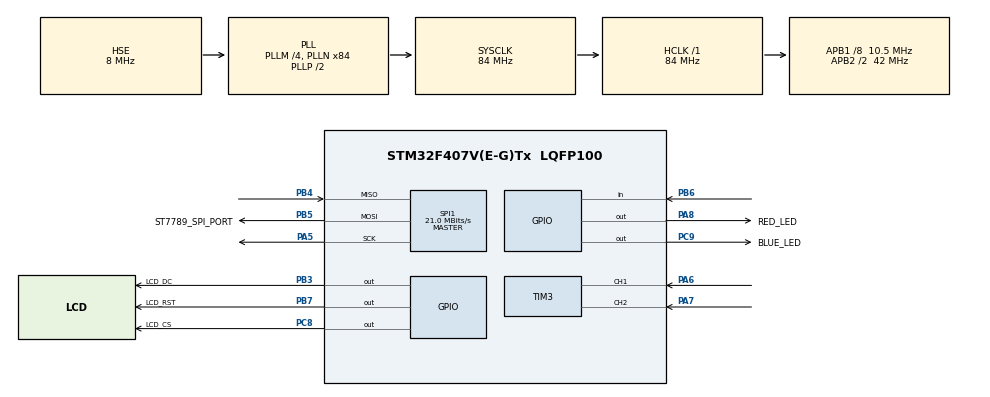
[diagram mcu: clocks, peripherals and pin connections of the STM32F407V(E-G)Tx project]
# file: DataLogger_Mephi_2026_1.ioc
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Mcu.Family=STM32F4
Mcu.Name=STM32F407V(E-G)Tx
Mcu.Package=LQFP100
NVIC.PriorityGroup=NVIC_PRIORITYGROUP_4
PA13.Mode=Serial_Wire
PA13.Signal=SYS_JTMS-SWDIO
PA14.Mode=Serial_Wire
PA14.Signal=SYS_JTCK-SWCLK
PA5.Mode=Full_Duplex_Master
PA5.Signal=SPI1_SCK
PA6.Signal=S_TIM3_CH1
PA7.Signal=S_TIM3_CH2
PA8.GPIO_Label=RED_LED
PA8.Signal=GPIO_Output
PB3.GPIO_Label=LCD_DC
PB3.Signal=GPIO_Output
PB4.Mode=Full_Duplex_Master
PB4.Signal=SPI1_MISO
PB5.GPIO_Label=ST7789_SPI_PORT
PB5.Mode=Full_Duplex_Master
PB5.Signal=SPI1_MOSI
PB6.GPIO_PuPd=GPIO_PULLUP
PB6.Signal=GPIO_Input
PB7.GPIO_Label=LCD_RST
PB7.Signal=GPIO_Output
PC8.GPIO_Label=LCD_CS
PC8.Signal=GPIO_Output
PC9.GPIO_Label=BLUE_LED
PC9.Signal=GPIO_Output
PH0-OSC_IN.Mode=HSE-External-Oscillator
PH0-OSC_IN.Signal=RCC_OSC_IN
PH1-OSC_OUT.Mode=HSE-External-Oscillator
PH1-OSC_OUT.Signal=RCC_OSC_OUT
ProjectManager.HeapSize=0x200
ProjectManager.StackSize=0x400
ProjectManager.TargetToolchain=CMake
RCC.48MHZClocksFreq_Value=42000000
RCC.AHBFreq_Value=84000000
RCC.APB1CLKDivider=RCC_HCLK_DIV8
RCC.APB1Freq_Value=10500000
RCC.APB1TimFreq_Value=21000000
RCC.APB2CLKDivider=RCC_HCLK_DIV2
RCC.APB2Freq_Value=42000000
RCC.APB2TimFreq_Value=84000000
RCC.CortexFreq_Value=84000000
RCC.HCLKFreq_Value=84000000
RCC.HSE_VALUE=8000000
RCC.HSI_VALUE=16000000
RCC.LSE_VALUE=32768
RCC.PLLM=4
RCC.PLLN=84
RCC.PLLSourceVirtual=RCC_PLLSOURCE_HSE
RCC.SYSCLKFreq_VALUE=84000000
RCC.SYSCLKSource=RCC_SYSCLKSOURCE_PLLCLK
RCC.VCOOutputFreq_Value=168000000
SH.S_TIM3_CH1.0=TIM3_CH1,Encoder_Interface
SH.S_TIM3_CH2.0=TIM3_CH2,Encoder_Interface
SPI1.CalculateBaudRate=21.0 MBits/s
SPI1.Direction=SPI_DIRECTION_2LINES
SPI1.Mode=SPI_MODE_MASTER
SPI1.VirtualType=VM_MASTER
TIM3.EncoderMode=TIM_ENCODERMODE_TI12
TIM3.IC1Polarity=TIM_ICPOLARITY_FALLING
TIM6.Period=999
TIM6.Prescaler=83
VP_TIM6_VS_ClockSourceINT.Mode=Enable_Timer
board=custom

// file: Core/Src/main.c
/* USER CODE BEGIN Header */
/**
  ******************************************************************************
  * @file           : main.c
  * @brief          : Main program body
  ******************************************************************************
  * @attention
  *
  * Copyright (c) 2026 STMicroelectronics.
  * All rights reserved.
  *
  * This software is licensed under terms that can be found in the LICENSE file
  * in the root directory of this software component.
  * If no LICENSE file comes with this software, it is provided AS-IS.
  *
  ******************************************************************************
  */
/* USER CODE END Header */
#include "main.h"

/* USER CODE BEGIN Includes */
#include "app/app.h"
#include "lcd.h"   // Драйвер ST7735
#include "ugui.h"
/* USER CODE END Includes */

SPI_HandleTypeDef hspi1;

TIM_HandleTypeDef htim3;
TIM_HandleTypeDef htim6;

void SystemClock_Config(void);
static void MX_GPIO_Init(void);
static void MX_TIM6_Init(void);
static void MX_TIM3_Init(void);
static void MX_SPI1_Init(void);

int main(void)
{

  /* MCU Configuration--------------------------------------------------------*/

  /* Reset of all peripherals, Initializes the Flash interface and the Systick. */
  HAL_Init();

  /* Configure the system clock */
  SystemClock_Config();

  /* Initialize all configured peripherals */
  MX_GPIO_Init();
  MX_TIM6_Init();
  MX_TIM3_Init();
  MX_SPI1_Init();
  /* USER CODE BEGIN 2 */
  HAL_TIM_Encoder_Start(&htim3, TIM_CHANNEL_ALL);
  /* USER CODE END 2 */

  /* Infinite loop */
  /* USER CODE BEGIN WHILE */
  LCD_init();
  LCD_PutStr(10, 10, "DataLogger", FONT_8X12, C_WHITE, C_BLACK);
  UG_DrawFrame(5, 30, 155, 120, C_BLUE);

  super_loop();
    /* USER CODE END WHILE */

}

void SystemClock_Config(void)
{
  RCC_OscInitTypeDef RCC_OscInitStruct = {0};
  RCC_ClkInitTypeDef RCC_ClkInitStruct = {0};

  /** Configure the main internal regulator output voltage
  */
  __HAL_RCC_PWR_CLK_ENABLE();
  __HAL_PWR_VOLTAGESCALING_CONFIG(PWR_REGULATOR_VOLTAGE_SCALE1);

  /** Initializes the RCC Oscillators according to the specified parameters
  * in the RCC_OscInitTypeDef structure.
  */
  RCC_OscInitStruct.OscillatorType = RCC_OSCILLATORTYPE_HSE;
  RCC_OscInitStruct.HSEState = RCC_HSE_ON;
  RCC_OscInitStruct.PLL.PLLState = RCC_PLL_ON;
  RCC_OscInitStruct.PLL.PLLSource = RCC_PLLSOURCE_HSE;
  RCC_OscInitStruct.PLL.PLLM = 4;
  RCC_OscInitStruct.PLL.PLLN = 84;
  RCC_OscInitStruct.PLL.PLLP = RCC_PLLP_DIV2;
  RCC_OscInitStruct.PLL.PLLQ = 4;
  if (HAL_RCC_OscConfig(&RCC_OscInitStruct) != HAL_OK)
  {
    Error_Handler();
  }

  /** Initializes the CPU, AHB and APB buses clocks
  */
  RCC_ClkInitStruct.ClockType = RCC_CLOCKTYPE_HCLK|RCC_CLOCKTYPE_SYSCLK
                              |RCC_CLOCKTYPE_PCLK1|RCC_CLOCKTYPE_PCLK2;
  RCC_ClkInitStruct.SYSCLKSource = RCC_SYSCLKSOURCE_PLLCLK;
  RCC_ClkInitStruct.AHBCLKDivider = RCC_SYSCLK_DIV1;
  RCC_ClkInitStruct.APB1CLKDivider = RCC_HCLK_DIV8;
  RCC_ClkInitStruct.APB2CLKDivider = RCC_HCLK_DIV2;

  if (HAL_RCC_ClockConfig(&RCC_ClkInitStruct, FLASH_LATENCY_2) != HAL_OK)
  {
    Error_Handler();
  }
}

static void MX_SPI1_Init(void)
{

  /* SPI1 parameter configuration*/
  hspi1.Instance = SPI1;
  hspi1.Init.Mode = SPI_MODE_MASTER;
  hspi1.Init.Direction = SPI_DIRECTION_2LINES;
  hspi1.Init.DataSize = SPI_DATASIZE_8BIT;
  hspi1.Init.CLKPolarity = SPI_POLARITY_LOW;
  hspi1.Init.CLKPhase = SPI_PHASE_1EDGE;
  hspi1.Init.NSS = SPI_NSS_SOFT;
  hspi1.Init.BaudRatePrescaler = SPI_BAUDRATEPRESCALER_2;
  hspi1.Init.FirstBit = SPI_FIRSTBIT_MSB;
  hspi1.Init.TIMode = SPI_TIMODE_DISABLE;
  hspi1.Init.CRCCalculation = SPI_CRCCALCULATION_DISABLE;
  hspi1.Init.CRCPolynomial = 10;
  if (HAL_SPI_Init(&hspi1) != HAL_OK)
  {
    Error_Handler();
  }

}

static void MX_TIM3_Init(void)
{

  TIM_Encoder_InitTypeDef sConfig = {0};
  TIM_MasterConfigTypeDef sMasterConfig = {0};

  htim3.Instance = TIM3;
  htim3.Init.Prescaler = 0;
  htim3.Init.CounterMode = TIM_COUNTERMODE_UP;
  htim3.Init.Period = 65535;
  htim3.Init.ClockDivision = TIM_CLOCKDIVISION_DIV1;
  htim3.Init.AutoReloadPreload = TIM_AUTORELOAD_PRELOAD_DISABLE;
  sConfig.EncoderMode = TIM_ENCODERMODE_TI12;
  sConfig.IC1Polarity = TIM_ICPOLARITY_FALLING;
  sConfig.IC1Selection = TIM_ICSELECTION_DIRECTTI;
  sConfig.IC1Prescaler = TIM_ICPSC_DIV1;
  sConfig.IC1Filter = 0;
  sConfig.IC2Polarity = TIM_ICPOLARITY_RISING;
  sConfig.IC2Selection = TIM_ICSELECTION_DIRECTTI;
  sConfig.IC2Prescaler = TIM_ICPSC_DIV1;
  sConfig.IC2Filter = 0;
  if (HAL_TIM_Encoder_Init(&htim3, &sConfig) != HAL_OK)
  {
    Error_Handler();
  }
  sMasterConfig.MasterOutputTrigger = TIM_TRGO_RESET;
  sMasterConfig.MasterSlaveMode = TIM_MASTERSLAVEMODE_DISABLE;
  if (HAL_TIMEx_MasterConfigSynchronization(&htim3, &sMasterConfig) != HAL_OK)
  {
    Error_Handler();
  }

}

static void MX_TIM6_Init(void)
{

  TIM_MasterConfigTypeDef sMasterConfig = {0};

  htim6.Instance = TIM6;
  htim6.Init.Prescaler = 83;
  htim6.Init.CounterMode = TIM_COUNTERMODE_UP;
  htim6.Init.Period = 999;
  htim6.Init.AutoReloadPreload = TIM_AUTORELOAD_PRELOAD_DISABLE;
  if (HAL_TIM_Base_Init(&htim6) != HAL_OK)
  {
    Error_Handler();
  }
  sMasterConfig.MasterOutputTrigger = TIM_TRGO_RESET;
  sMasterConfig.MasterSlaveMode = TIM_MASTERSLAVEMODE_DISABLE;
  if (HAL_TIMEx_MasterConfigSynchronization(&htim6, &sMasterConfig) != HAL_OK)
  {
    Error_Handler();
  }

}

static void MX_GPIO_Init(void)
{
  GPIO_InitTypeDef GPIO_InitStruct = {0};

  /* GPIO Ports Clock Enable */
  __HAL_RCC_GPIOH_CLK_ENABLE();
  __HAL_RCC_GPIOA_CLK_ENABLE();
  __HAL_RCC_GPIOC_CLK_ENABLE();
  __HAL_RCC_GPIOB_CLK_ENABLE();

  /*Configure GPIO pin Output Level */
  HAL_GPIO_WritePin(GPIOC, LCD_CS_Pin|BLUE_LED_Pin, GPIO_PIN_RESET);

  /*Configure GPIO pin Output Level */
  HAL_GPIO_WritePin(RED_LED_GPIO_Port, RED_LED_Pin, GPIO_PIN_RESET);

  /*Configure GPIO pin Output Level */
  HAL_GPIO_WritePin(GPIOB, LCD_DC_Pin|LCD_RST_Pin, GPIO_PIN_RESET);

  /*Configure GPIO pins : LCD_CS_Pin BLUE_LED_Pin */
  GPIO_InitStruct.Pin = LCD_CS_Pin|BLUE_LED_Pin;
  GPIO_InitStruct.Mode = GPIO_MODE_OUTPUT_PP;
  GPIO_InitStruct.Pull = GPIO_NOPULL;
  GPIO_InitStruct.Speed = GPIO_SPEED_FREQ_LOW;
  HAL_GPIO_Init(GPIOC, &GPIO_InitStruct);

  /*Configure GPIO pin : RED_LED_Pin */
  GPIO_InitStruct.Pin = RED_LED_Pin;
  GPIO_InitStruct.Mode = GPIO_MODE_OUTPUT_PP;
  GPIO_InitStruct.Pull = GPIO_NOPULL;
  GPIO_InitStruct.Speed = GPIO_SPEED_FREQ_LOW;
  HAL_GPIO_Init(RED_LED_GPIO_Port, &GPIO_InitStruct);

  /*Configure GPIO pins : LCD_DC_Pin LCD_RST_Pin */
  GPIO_InitStruct.Pin = LCD_DC_Pin|LCD_RST_Pin;
  GPIO_InitStruct.Mode = GPIO_MODE_OUTPUT_PP;
  GPIO_InitStruct.Pull = GPIO_NOPULL;
  GPIO_InitStruct.Speed = GPIO_SPEED_FREQ_LOW;
  HAL_GPIO_Init(GPIOB, &GPIO_InitStruct);

  /*Configure GPIO pin : PB6 */
  GPIO_InitStruct.Pin = GPIO_PIN_6;
  GPIO_InitStruct.Mode = GPIO_MODE_INPUT;
  GPIO_InitStruct.Pull = GPIO_PULLUP;
  HAL_GPIO_Init(GPIOB, &GPIO_InitStruct);

}

void Error_Handler(void)
{
  __disable_irq();
  while (1)
  {
  }
}
